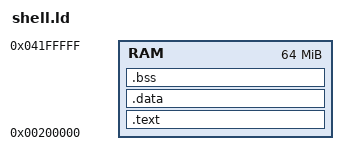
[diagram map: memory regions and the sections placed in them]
ENTRY(main)

MEMORY
{
    RAM : ORIGIN = 0x200000, LENGTH = 64M
}

SECTIONS
{
    .text : {
        *(.text*)
        *(.rodata*)
    } > RAM

    .data : {
        *(.data*)
    } > RAM

    .bss : {
        *(.bss*)
        *(COMMON)
    } > RAM
}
